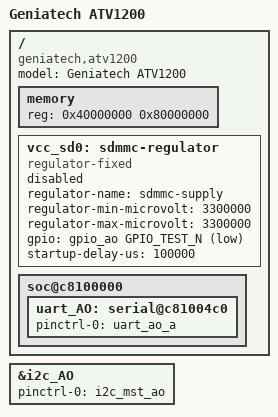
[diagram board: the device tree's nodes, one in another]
/*
 * Copyright 2014 Carlo Caione <carlo@caione.org>
 *
 * This program is free software; you can redistribute it and/or modify it
 * under the terms of the GNU General Public License as published by the
 * Free Software Foundation; either version 2 of the License, or (at your
 * option) any later version.
 */

/dts-v1/;

#include <dt-bindings/gpio/meson8-gpio.h>
#include "meson6.dtsi"

/ {
	model = "Geniatech ATV1200";
	compatible = "geniatech,atv1200";

	memory {
		reg = <0x40000000 0x80000000>;
	};

	vcc_sd0: sdmmc-regulator {
		compatible = "regulator-fixed";
		regulator-name = "sdmmc-supply";
		regulator-min-microvolt = <3300000>;
		regulator-max-microvolt = <3300000>;
		gpio = <&gpio_ao GPIO_TEST_N 1>;
		startup-delay-us = <100000>;
		status = "disabled";
	};

	soc@c8100000 {
		uart_AO: serial@c81004c0 {
			status = "okay";
			pinctrl-0 = <&uart_ao_a>;
			pinctrl-names = "default";
		};
	};
}; /* end of / */

&i2c_AO {
	status = "okay";
	pinctrl-0 = <&i2c_mst_ao>;
	pinctrl-names = "default";

	/*
	pmic@32 {
		compatible = "ricoh,rn5t618";
		reg = <0x32>;

		regulators {
			DCDC1 {
				regulator-min-microvolt = <1050000>;
				regulator-max-microvolt = <1050000>;
				regulator-always-on;
			};

			DCDC2 {
				regulator-min-microvolt = <1175000>;
				regulator-max-microvolt = <1175000>;
				regulator-always-on;
			};
                };
	};
	*/
};
